AUTOSAR XML (schema 4-0-1)
standard types defined: void, sint8, sint16, sint32, uint8, uint16, uint32, sint8_least, sint16_least, sint32_least, uint8_least, uint16_least, uint32_least, float32, float64, boolean
package /AUTOSAR_PlatformTypes/CompuMethods
  compu method boolean_Literals: 0=FALSE, 1=TRUE
package /SoftwarePkg/SoftwareComponentPkg
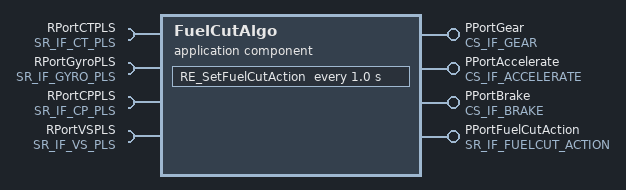
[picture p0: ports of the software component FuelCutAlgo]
  application sw component type FuelCutAlgo
    4 x provide port:
      PPortGear: server-com-spec{operation=SetGearLevel, queue-length=1}, provided-interface=CS_IF_GEAR
      PPortAccelerate: server-com-spec{operation=SetAccelerateLevel, queue-length=1}, provided-interface=CS_IF_ACCELERATE
      PPortBrake: server-com-spec{operation=SetBrakeLevel, queue-length=1}, provided-interface=CS_IF_BRAKE
      PPortFuelCutAction: provided-interface=SR_IF_FUELCUT_ACTION
    4 x require port:
      RPortCTPLS: required-interface=SR_IF_CT_PLS
      RPortGyroPLS: required-interface=SR_IF_GYRO_PLS
      RPortCPPLS: required-interface=SR_IF_CP_PLS
      RPortVSPLS: required-interface=SR_IF_VS_PLS
    behavior IB_FuelCutAlgo: handle-termination-and-restart=NO-SUPPORT, supports-multiple-instantiation=true
      4 x data received event:
        DRE_VehicleSpeedPls: start-on-event=RE_SetVehicleSpeed, data=RPortVSPLS.vehicleSpeed_pls
        DRE_CrankshaftPositionPls: start-on-event=RE_SetCrankshaftPosition, data=RPortCPPLS.crankshaftPosition_pls
        DRE_GyroPls: start-on-event=RE_SetGyro, data=RPortGyroPLS.gyro_pls
        DRE_CoolantTempertaturePls: start-on-event=RE_SetCoolantTemperature, data=RPortCTPLS.coolantTemperature_pls
      operation invoked event OIE_SetBrakeLevel: start-on-event=RE_SetBrake, operation=PPortBrake.SetBrakeLevel
      operation invoked event OIE_SetAccelerateLevel: start-on-event=RE_SetAccelerate, operation=PPortAccelerate.SetAccelerateLevel
      operation invoked event OIE_SetGearLevel: start-on-event=RE_SetGear, operation=PPortGear.SetGearLevel
      timing event TE_SetFuelCutState: start-on-event=RE_SetFuelCutAction, period=1.0
      explicit-inter-runnable-variables:
        7 x data:
          eX_BrakeLevel: type=uint8
          eX_AccelerateLevel: type=uint8
          eX_GearLevel: type=uint8
          eX_VehicleSpeed: type=float32
          eX_CrankshaftPosition: type=float32
          eX_Gyro: type=float32
          eX_CoolantTemperature: type=float32
      8 x runnable, all with can-be-invoked-concurrently=true:
        RE_SetBrake: symbol=SetBrake
          written-local-variables:
            access WLV_BrakeLevel: accessed-variable=eX_BrakeLevel
        RE_SetAccelerate: symbol=SetAccelerate
          written-local-variables:
            access WLV_AccelerateLevel: accessed-variable=eX_AccelerateLevel
        RE_SetGear: symbol=SetGear
          written-local-variables:
            access WLV_GearLevel: accessed-variable=eX_GearLevel
        RE_SetVehicleSpeed: symbol=SetVehicleSpeed
          data-read-access:
            access DRA_VehicleSpeedPls: accessed-variable=RPortVSPLS.vehicleSpeed_pls
          written-local-variables:
            access WLV_VehicleSpeed: accessed-variable=eX_VehicleSpeed
        RE_SetCrankshaftPosition: symbol=SetCrankshaftPosition
          data-read-access:
            access DRA_CrankshaftPositionPls: accessed-variable=RPortCPPLS.crankshaftPosition_pls
          written-local-variables:
            access WLV_CrankshaftPosition: accessed-variable=eX_CrankshaftPosition
        RE_SetGyro: symbol=SetGyro
          data-read-access:
            access DRA_GyroPls: accessed-variable=RPortGyroPLS.gyro_pls
          written-local-variables:
            access WLV_Gyro: accessed-variable=eX_Gyro
        RE_SetCoolantTemperature: symbol=SetCoolantTemperature
          data-read-access:
            access DRA_CoolantTemperaturePls: accessed-variable=RPortCTPLS.coolantTemperature_pls
          written-local-variables:
            access WLV_CoolantTemperature: accessed-variable=eX_CoolantTemperature
        RE_SetFuelCutAction: symbol=SetFuelCutAction
          data-write-access:
            access DWA_FuelCutAction: accessed-variable=PPortFuelCutAction.fuelCutAction
          read-local-variables:
            7 x access:
              RLV_BrakeLevel: accessed-variable=eX_BrakeLevel
              RLV_AccelerateLevel: accessed-variable=eX_AccelerateLevel
              RLS_GearLevel: accessed-variable=eX_GearLevel
              RLV_VehicleSpeed: accessed-variable=eX_VehicleSpeed
              RLV_CrankshaftPosition: accessed-variable=eX_CrankshaftPosition
              RLV_Gyro: accessed-variable=eX_Gyro
              RLV_CoolantTemperature: accessed-variable=eX_CoolantTemperature
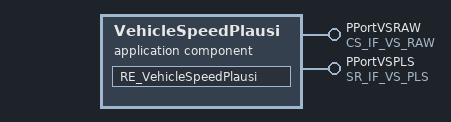
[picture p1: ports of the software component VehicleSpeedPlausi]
  application sw component type VehicleSpeedPlausi
    provide port PPortVSRAW: server-com-spec{operation=SetVehicleSpeedRaw, queue-length=1}, provided-interface=CS_IF_VS_RAW
    provide port PPortVSPLS: provided-interface=SR_IF_VS_PLS
    behavior IB_VehicleSpeedPlausi: handle-termination-and-restart=NO-SUPPORT, supports-multiple-instantiation=true
      operation invoked event OIE_SetVehicleSpeedRaw: start-on-event=RE_VehicleSpeedPlausi, operation=PPortVSRAW.SetVehicleSpeedRaw
      runnable RE_VehicleSpeedPlausi: can-be-invoked-concurrently=true, symbol=VehicleSpeedPlausi
        data-write-access:
          access DWA_SetVehicleSpeedPls: accessed-variable=PPortVSPLS.vehicleSpeed_pls
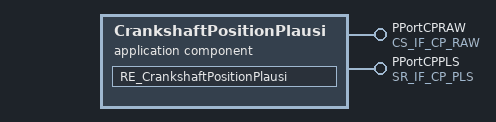
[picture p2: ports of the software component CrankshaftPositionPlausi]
  application sw component type CrankshaftPositionPlausi
    provide port PPortCPRAW: server-com-spec{operation=SetCrankshaftPositionRaw, queue-length=1}, provided-interface=CS_IF_CP_RAW
    provide port PPortCPPLS: provided-interface=SR_IF_CP_PLS
    behavior IB_CrankshaftPositionPlausi: handle-termination-and-restart=NO-SUPPORT, supports-multiple-instantiation=true
      operation invoked event OIE_SetCrankshaftPositionRaw: start-on-event=RE_CrankshaftPositionPlausi, operation=PPortCPRAW.SetCrankshaftPositionRaw
      runnable RE_CrankshaftPositionPlausi: can-be-invoked-concurrently=true, symbol=CrankshaftPositionPlausi
        data-write-access:
          access DWA_SetCrankshaftPositioinPls: accessed-variable=PPortCPPLS.crankshaftPosition_pls
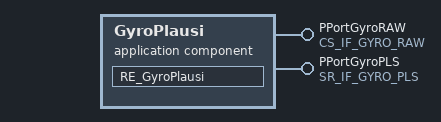
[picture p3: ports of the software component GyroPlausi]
  application sw component type GyroPlausi
    provide port PPortGyroRAW: server-com-spec{operation=SetGyroRaw, queue-length=1}, provided-interface=CS_IF_GYRO_RAW
    provide port PPortGyroPLS: provided-interface=SR_IF_GYRO_PLS
    behavior IB_GyroPlausi: handle-termination-and-restart=NO-SUPPORT, supports-multiple-instantiation=true
      operation invoked event OIE_SetGyroRaw: start-on-event=RE_GyroPlausi, operation=PPortGyroRAW.SetGyroRaw
      runnable RE_GyroPlausi: can-be-invoked-concurrently=true, symbol=GyroPlausi
        data-write-access:
          access DWA_SetGyroPls: accessed-variable=PPortGyroPLS.gyro_pls
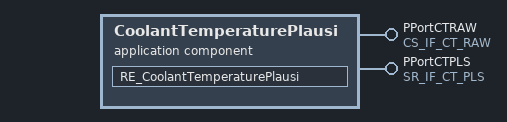
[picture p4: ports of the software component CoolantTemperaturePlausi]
  application sw component type CoolantTemperaturePlausi
    provide port PPortCTRAW: server-com-spec{operation=SetCoolantTemperatureRaw, queue-length=1}, provided-interface=CS_IF_CT_RAW
    provide port PPortCTPLS: provided-interface=SR_IF_CT_PLS
    behavior IB_CoolantTemperaturePlausi: handle-termination-and-restart=NO-SUPPORT, supports-multiple-instantiation=true
      operation invoked event OIE_SetCoolantTemperatureRaw: start-on-event=RE_CoolantTemperaturePlausi, operation=PPortCTRAW.SetCoolantTemperatureRaw
      runnable RE_CoolantTemperaturePlausi: can-be-invoked-concurrently=true, symbol=CoolantTemperaturePlausi
        data-write-access:
          access DWA_SetCoolantTemperaturePls: accessed-variable=PPortCTPLS.coolantTemperature_pls
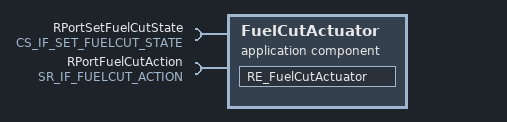
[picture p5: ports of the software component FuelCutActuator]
  application sw component type FuelCutActuator
    require port RPortSetFuelCutState: client-com-spec=SetFuelCutState, required-interface=CS_IF_SET_FUELCUT_STATE
    require port RPortFuelCutAction: required-interface=SR_IF_FUELCUT_ACTION
    behavior IB_FuelCutActuator: handle-termination-and-restart=NO-SUPPORT, supports-multiple-instantiation=true
      data received event DRE_FuelCutAction: start-on-event=RE_FuelCutActuator, data=RPortFuelCutAction.fuelCutAction
      runnable RE_FuelCutActuator: can-be-invoked-concurrently=true, symbol=FuelCutActuator
        data-read-access:
          access DRA_FuelCutAction: accessed-variable=RPortFuelCutAction.fuelCutAction
        async call ASCP_SetFuelCutState: operation=RPortSetFuelCutState.SetFuelCutState
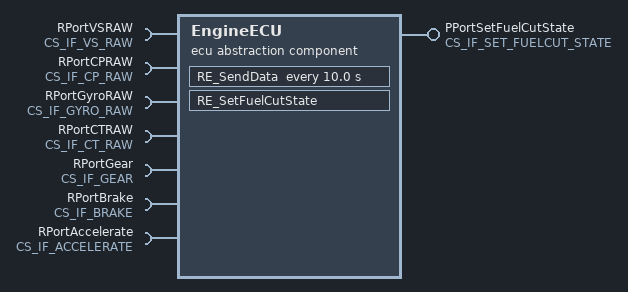
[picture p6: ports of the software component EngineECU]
  ecu abstraction sw component type EngineECU
    provide port PPortSetFuelCutState: server-com-spec{operation=SetFuelCutState, queue-length=1}, provided-interface=CS_IF_SET_FUELCUT_STATE
    7 x require port:
      RPortVSRAW: client-com-spec=SetVehicleSpeedRaw, required-interface=CS_IF_VS_RAW
      RPortCPRAW: client-com-spec=SetCrankshaftPositionRaw, required-interface=CS_IF_CP_RAW
      RPortGyroRAW: client-com-spec=SetGyroRaw, required-interface=CS_IF_GYRO_RAW
      RPortCTRAW: client-com-spec=SetCoolantTemperatureRaw, required-interface=CS_IF_CT_RAW
      RPortGear: client-com-spec=SetGearLevel, required-interface=CS_IF_GEAR
      RPortBrake: client-com-spec=SetBrakeLevel, required-interface=CS_IF_BRAKE
      RPortAccelerate: client-com-spec=SetAccelerateLevel, required-interface=CS_IF_ACCELERATE
    behavior IB_EngineECU: handle-termination-and-restart=NO-SUPPORT, supports-multiple-instantiation=true
      operation invoked event OIE_SetFuelCutState: start-on-event=RE_SetFuelCutState, operation=PPortSetFuelCutState.SetFuelCutState
      timing event TE_SendData: start-on-event=RE_SendData, period=10.0
      explicit-inter-runnable-variables:
        data eX_FuelCutState: type=uint8
      runnable RE_SetFuelCutState: can-be-invoked-concurrently=true, symbol=SetFuelCutState
        written-local-variables:
          access WLV_FuelCutState: accessed-variable=eX_FuelCutState
      runnable RE_SendData: can-be-invoked-concurrently=true, symbol=SendData
        7 x async call:
          ASCP_SetVehicleSpeedRaw: operation=RPortVSRAW.SetVehicleSpeedRaw
          ASCP_SetCrankshaftPositionRaw: operation=RPortCPRAW.SetCrankshaftPositionRaw
          ASCP_SetGyroRaw: operation=RPortGyroRAW.SetGyroRaw
          ASCP_SetCoolantTemperatureRaw: operation=RPortCTRAW.SetCoolantTemperatureRaw
          ASCP_SetBrakeState: operation=RPortBrake.SetBrakeLevel
          ASCP_SetAccelerate: operation=RPortAccelerate.SetAccelerateLevel
          ASCP_SetGearState: operation=RPortGear.SetGearLevel
package /SoftwarePkg/PortInterfacePkg
  8 x client server interface:
    CS_IF_SET_FUELCUT_STATE
      operation SetFuelCutState
        arg fuelCutState: type=uint8, direction=IN
    CS_IF_VS_RAW
      operation SetVehicleSpeedRaw
        arg vehicleSpeedRaw: type=float32, direction=IN
    CS_IF_CP_RAW
      operation SetCrankshaftPositionRaw
        arg crankshaftPositionRaw: type=float32, direction=IN
    CS_IF_GYRO_RAW
      operation SetGyroRaw
        arg gyroRaw: type=float32, direction=IN
    CS_IF_CT_RAW
      operation SetCoolantTemperatureRaw
        arg coolantTemperatureRaw: type=float32, direction=IN
    CS_IF_GEAR
      operation SetGearLevel
        arg gearLevel: type=uint8, direction=IN
    CS_IF_ACCELERATE
      operation SetAccelerateLevel
        arg accelerateLevel: type=uint8, direction=IN
    CS_IF_BRAKE
      operation SetBrakeLevel
        arg brakeLevel: type=uint8, direction=IN
  5 x sender receiver interface:
    SR_IF_CT_PLS
      data coolantTemperature_pls: type=float32
    SR_IF_GYRO_PLS
      data gyro_pls: type=float32
    SR_IF_CP_PLS
      data crankshaftPosition_pls: type=float32
    SR_IF_VS_PLS
      data vehicleSpeed_pls: type=float32
    SR_IF_FUELCUT_ACTION
      data fuelCutAction: type=uint8
